# HDSC_HC32L166 register map
Vendor: HDSC Co.Ltd; Series: ARMCM0P; File version: 1.2
CPU: CM0 r0p0, little endian, no MPU, no FPU, 3 interrupt priority bits
Registers are 32-bit, read-write, reset 0x0 unless marked. A register's access mark holds for its fields unless they carry their own. Offsets are from the block's base; [hi:lo] are bit positions; {n}, {i} and the like mark numbered series; 'fields as' and 'values as' point back to an identical list.

## TIM0_MODE23
Base 0x40000C00; alternate view of TIM0_MODE0
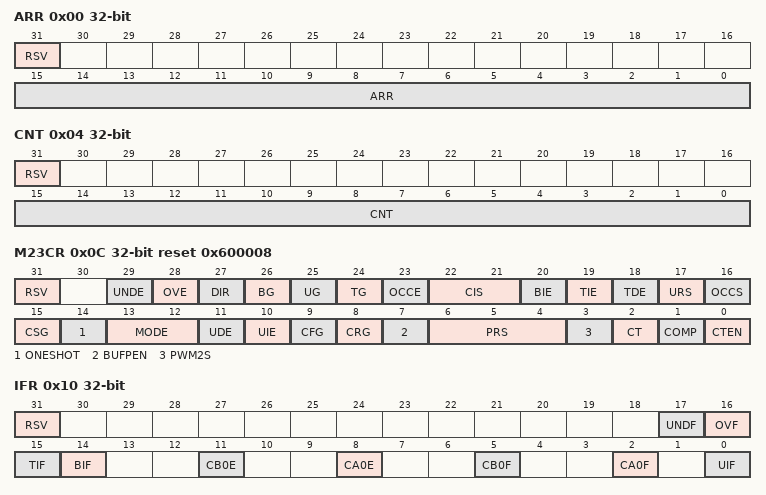
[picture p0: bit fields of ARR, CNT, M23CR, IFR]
0x00 ARR (reset mask 0xFFFF)
  [31] RSV, [15:0] ARR
0x04 CNT (reset mask 0xFFFF)
  [31] RSV, [15:0] CNT
0x0C M23CR reset 0x600008 (reset mask 0x3FFFFFFF)
  [31] RSV, [29] UNDE, [28] OVE, [27] DIR, [26] BG wo, [25] UG wo, [24] TG wo, [23] OCCE, [22:21] CIS, [20] BIE, [19] TIE, [18] TDE, [17] URS, [16] OCCS, [15] CSG, [14] ONESHOT, [13:12] MODE, [11] UDE, [10] UIE, [9] CFG, [8] CRG, [7] BUFPEN, [6:4] PRS, [3] PWM2S, [2] CT, [1] COMP, [0] CTEN
0x10 IFR ro (reset mask 0x3C925)
  [31] RSV, [17] UNDF, [16] OVF, [15] TIF, [14] BIF, [11] CB0E, [8] CA0E, [5] CB0F, [2] CA0F, [0] UIF
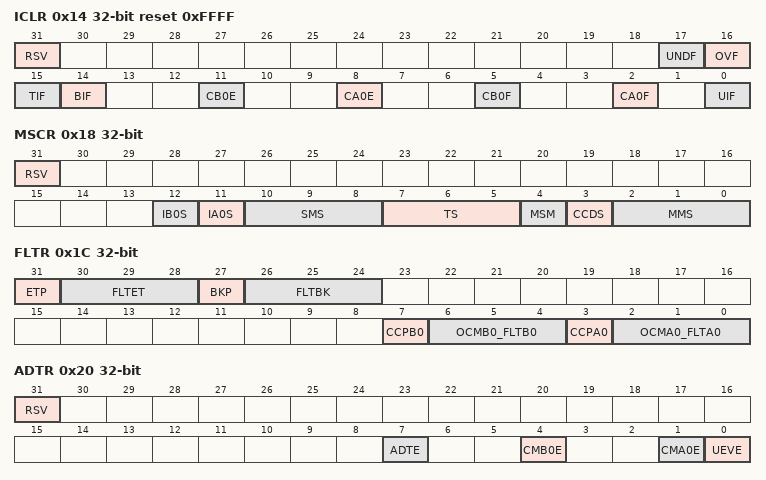
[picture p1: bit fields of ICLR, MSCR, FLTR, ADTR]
0x14 ICLR wo reset 0xFFFF (reset mask 0x3C925)
  [31] RSV rw, [17] UNDF rw, [16] OVF rw, [15] TIF, [14] BIF, [11] CB0E, [8] CA0E, [5] CB0F, [2] CA0F, [0] UIF
0x18 MSCR (reset mask 0x1FFF)
  [31] RSV, [12] IB0S, [11] IA0S, [10:8] SMS, [7:5] TS, [4] MSM, [3] CCDS, [2:0] MMS
0x1C FLTR
  [31] ETP, [30:28] FLTET, [27] BKP, [26:24] FLTBK, [7] CCPB0, [6:4] OCMB0_FLTB0, [3] CCPA0, [2:0] OCMA0_FLTA0
0x20 ADTR (reset mask 0x93)
  [31] RSV, [7] ADTE, [4] CMB0E, [1] CMA0E, [0] UEVE
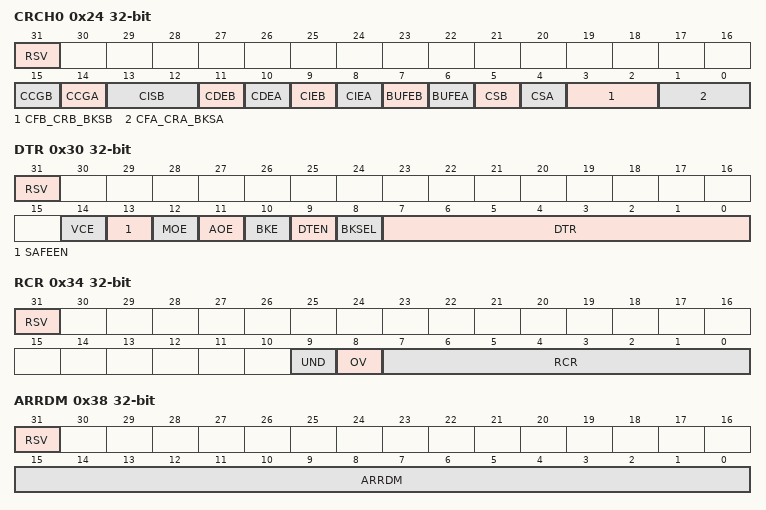
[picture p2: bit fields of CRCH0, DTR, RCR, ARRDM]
0x24 CRCH0 (reset mask 0xFFFF)
  [31] RSV, [15] CCGB, [14] CCGA, [13:12] CISB, [11] CDEB, [10] CDEA, [9] CIEB, [8] CIEA, [7] BUFEB, [6] BUFEA, [5] CSB, [4] CSA, [3:2] CFB_CRB_BKSB, [1:0] CFA_CRA_BKSA
0x30 DTR (reset mask 0x7FFF)
  [31] RSV, [14] VCE, [13] SAFEEN, [12] MOE, [11] AOE, [10] BKE, [9] DTEN, [8] BKSEL, [7:0] DTR
0x34 RCR (reset mask 0x3FF)
  [31] RSV, [9] UND, [8] OV, [7:0] RCR
0x38 ARRDM (reset mask 0xFFFF)
  [31] RSV, [15:0] ARRDM
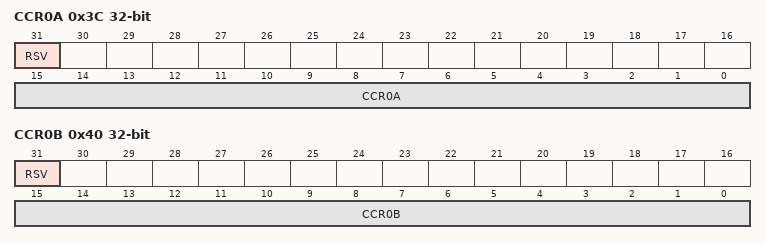
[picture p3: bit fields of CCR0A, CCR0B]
0x3C CCR0A (reset mask 0xFFFF)
  [31] RSV, [15:0] CCR0A
0x40 CCR0B (reset mask 0xFFFF)
  [31] RSV, [15:0] CCR0B

## TIM1_MODE23
Base 0x40000D00; alternate view of TIM1_MODE0
Registers as TIM0_MODE23.

## TIM2_MODE23
Base 0x40000E00; alternate view of TIM2_MODE0
Registers as TIM0_MODE23.

## TIM3_MODE23
Base 0x40005800; alternate view of TIM3_MODE0
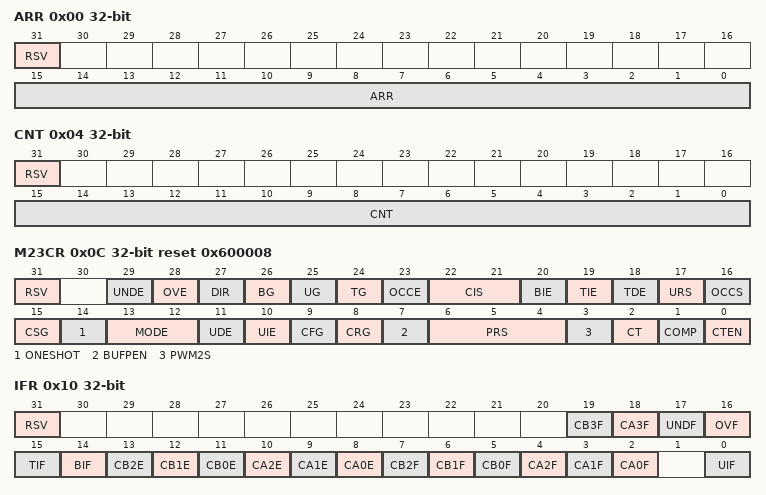
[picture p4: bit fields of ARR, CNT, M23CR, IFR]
0x00 ARR (reset mask 0xFFFF)
  [31] RSV, [15:0] ARR
0x04 CNT (reset mask 0xFFFF)
  [31] RSV, [15:0] CNT
0x0C M23CR reset 0x600008 (reset mask 0x3FFFFFFF)
  [31] RSV, [29] UNDE, [28] OVE, [27] DIR, [26] BG wo, [25] UG wo, [24] TG wo, [23] OCCE, [22:21] CIS, [20] BIE, [19] TIE, [18] TDE, [17] URS, [16] OCCS, [15] CSG, [14] ONESHOT, [13:12] MODE, [11] UDE, [10] UIE, [9] CFG, [8] CRG, [7] BUFPEN, [6:4] PRS, [3] PWM2S, [2] CT, [1] COMP, [0] CTEN
0x10 IFR ro (reset mask 0xFFFFD)
  [31] RSV, [19] CB3F, [18] CA3F, [17] UNDF, [16] OVF, [15] TIF, [14] BIF, [13] CB2E, [12] CB1E, [11] CB0E, [10] CA2E, [9] CA1E, [8] CA0E, [7] CB2F, [6] CB1F, [5] CB0F, [4] CA2F, [3] CA1F, [2] CA0F, [0] UIF
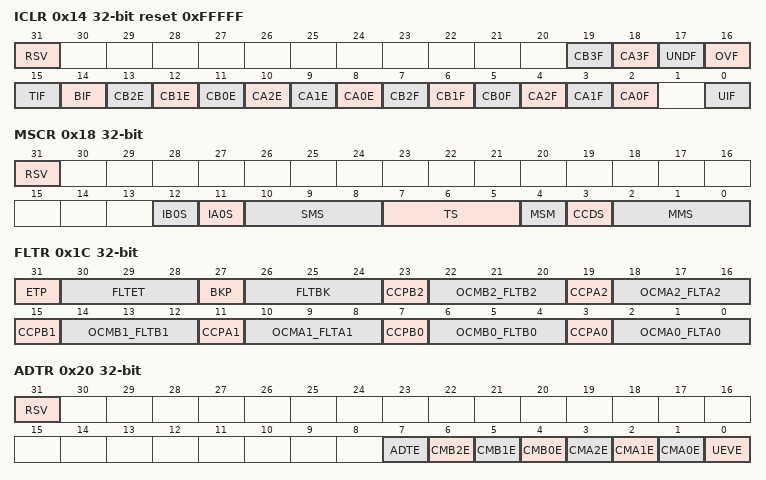
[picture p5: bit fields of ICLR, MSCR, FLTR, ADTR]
0x14 ICLR wo reset 0xFFFFF (reset mask 0xFFFFD)
  [31] RSV rw, [19] CB3F rw, [18] CA3F rw, [17] UNDF rw, [16] OVF rw, [15] TIF, [14] BIF, [13] CB2E, [12] CB1E, [11] CB0E, [10] CA2E, [9] CA1E, [8] CA0E, [7] CB2F, [6] CB1F, [5] CB0F, [4] CA2F, [3] CA1F, [2] CA0F, [0] UIF
0x18 MSCR (reset mask 0x1FFF)
  [31] RSV, [12] IB0S, [11] IA0S, [10:8] SMS, [7:5] TS, [4] MSM, [3] CCDS, [2:0] MMS
0x1C FLTR
  [31] ETP, [30:28] FLTET, [27] BKP, [26:24] FLTBK, [23] CCPB2, [22:20] OCMB2_FLTB2, [19] CCPA2, [18:16] OCMA2_FLTA2, [15] CCPB1, [14:12] OCMB1_FLTB1, [11] CCPA1, [10:8] OCMA1_FLTA1, [7] CCPB0, [6:4] OCMB0_FLTB0, [3] CCPA0, [2:0] OCMA0_FLTA0
0x20 ADTR (reset mask 0xFF)
  [31] RSV, [7] ADTE, [6] CMB2E, [5] CMB1E, [4] CMB0E, [3] CMA2E, [2] CMA1E, [1] CMA0E, [0] UEVE
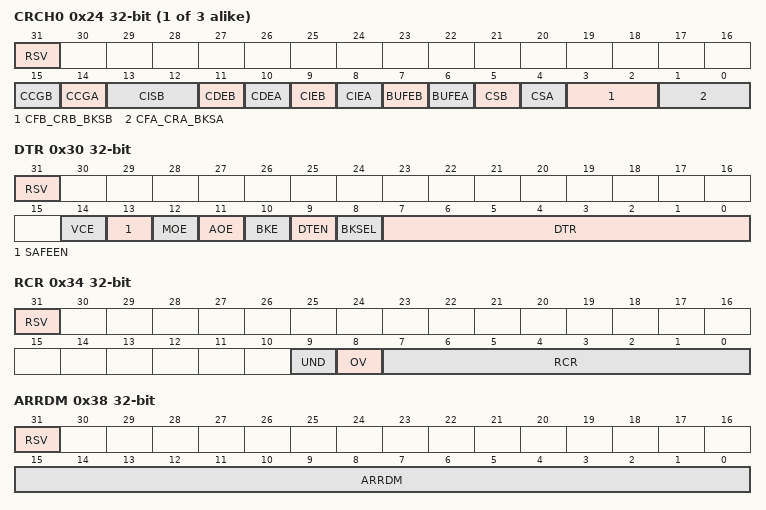
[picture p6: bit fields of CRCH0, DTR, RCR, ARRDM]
{0x24+4i} CRCH{i} (reset mask 0xFFFF) (i=0..2)
  [31] RSV, [15] CCGB, [14] CCGA, [13:12] CISB, [11] CDEB, [10] CDEA, [9] CIEB, [8] CIEA, [7] BUFEB, [6] BUFEA, [5] CSB, [4] CSA, [3:2] CFB_CRB_BKSB, [1:0] CFA_CRA_BKSA
0x30 DTR (reset mask 0x7FFF)
  [31] RSV, [14] VCE, [13] SAFEEN, [12] MOE, [11] AOE, [10] BKE, [9] DTEN, [8] BKSEL, [7:0] DTR
0x34 RCR (reset mask 0x3FF)
  [31] RSV, [9] UND, [8] OV, [7:0] RCR
0x38 ARRDM (reset mask 0xFFFF)
  [31] RSV, [15:0] ARRDM
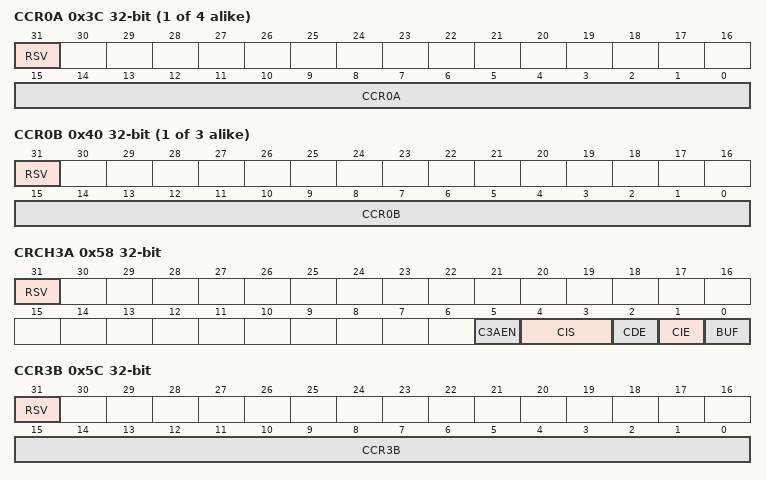
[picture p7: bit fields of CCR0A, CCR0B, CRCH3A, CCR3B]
{0x3C+8i} CCR{i}A (reset mask 0xFFFF) (i=0..3)
  [31] RSV, [15:0] CCR{i}A
{0x40+8i} CCR{i}B (reset mask 0xFFFF) (i=0..2)
  [31] RSV, [15:0] CCR{i}B
0x58 CRCH3A (reset mask 0x3F)
  [31] RSV, [5] C3AEN, [4:3] CIS, [2] CDE, [1] CIE, [0] BUF
0x5C CCR3B (reset mask 0xFFFF)
  [31] RSV, [15:0] CCR3B
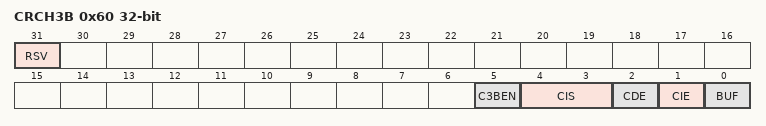
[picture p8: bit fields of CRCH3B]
0x60 CRCH3B (reset mask 0x3F)
  [31] RSV, [5] C3BEN, [4:3] CIS, [2] CDE, [1] CIE, [0] BUF

## TRNG
Base 0x40004C00
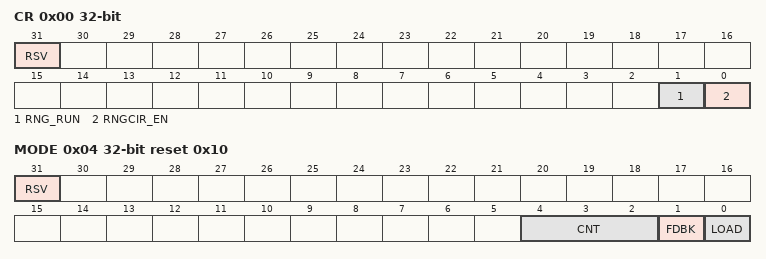
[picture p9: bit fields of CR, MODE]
0x00 CR (reset mask 0x3)
  [31] RSV, [1] RNG_RUN, [0] RNGCIR_EN
0x04 MODE reset 0x10 (reset mask 0x1F)
  [31] RSV, [4:2] CNT, [1] FDBK, [0] LOAD
0x0C DATA0 ro
0x10 DATA1 ro

## UART0 — desc UART
Base 0x40000000
Same registers: UART1 0x40000100, UART2 0x40006000, UART3 0x40006400
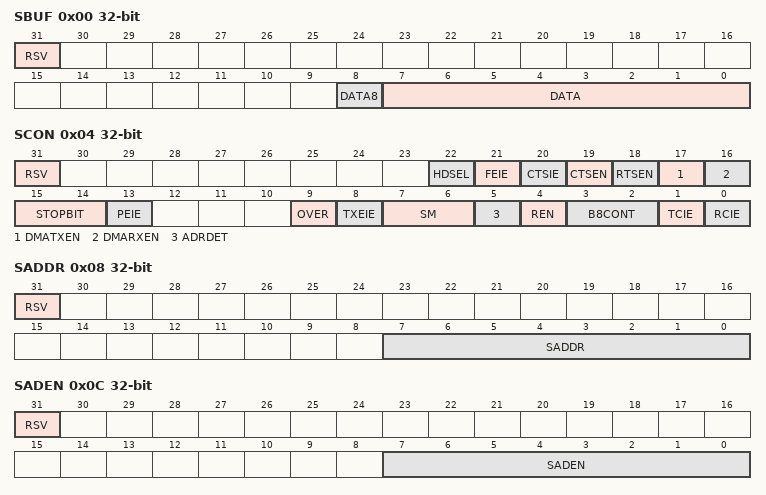
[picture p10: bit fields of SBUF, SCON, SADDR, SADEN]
0x00 SBUF (reset mask 0x1FF)
  [31] RSV, [8] DATA8, [7:0] DATA
0x04 SCON (reset mask 0x7FE3FF)
  [31] RSV, [22] HDSEL, [21] FEIE, [20] CTSIE, [19] CTSEN, [18] RTSEN, [17] DMATXEN, [16] DMARXEN, [15:14] STOPBIT, [13] PEIE, [9] OVER, [8] TXEIE, [7:6] SM, [5] ADRDET, [4] REN, [3:2] B8CONT, [1] TCIE, [0] RCIE
0x08 SADDR (reset mask 0xFF)
  [31] RSV, [7:0] SADDR
0x0C SADEN (reset mask 0xFF)
  [31] RSV, [7:0] SADEN
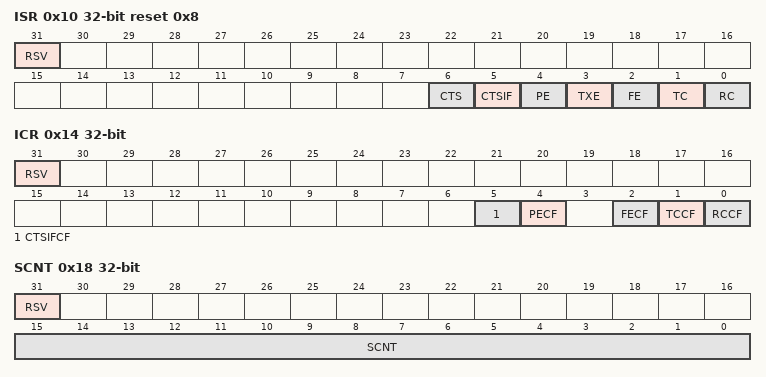
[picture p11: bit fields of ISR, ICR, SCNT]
0x10 ISR ro reset 0x8 (reset mask 0x7F)
  [31] RSV rw, [6] CTS, [5] CTSIF, [4] PE, [3] TXE, [2] FE, [1] TC, [0] RC
0x14 ICR wo (reset mask 0x37)
  [31] RSV rw, [5] CTSIFCF, [4] PECF, [2] FECF, [1] TCCF, [0] RCCF
0x18 SCNT (reset mask 0xFFFF)
  [31] RSV, [15:0] SCNT

## VC
Base 0x40002400; alternate view of ADC
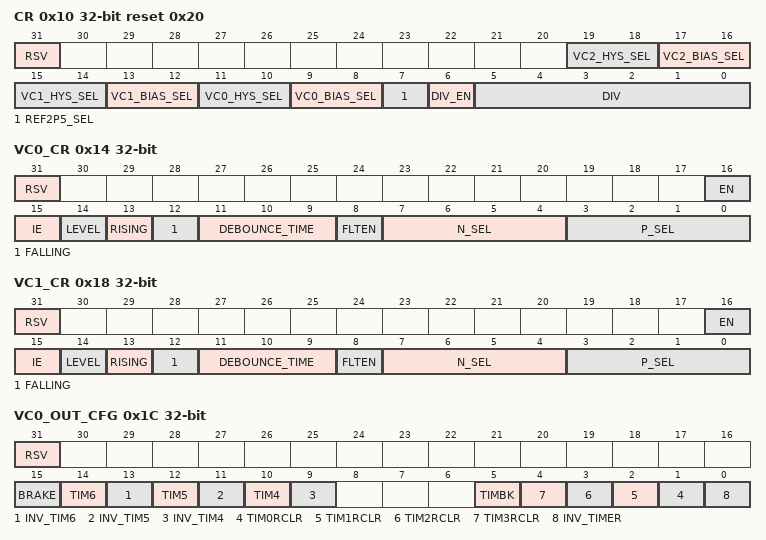
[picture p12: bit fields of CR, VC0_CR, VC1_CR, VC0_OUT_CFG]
0x10 CR reset 0x20 (reset mask 0xFFFFF)
  [31] RSV, [19:18] VC2_HYS_SEL, [17:16] VC2_BIAS_SEL, [15:14] VC1_HYS_SEL, [13:12] VC1_BIAS_SEL, [11:10] VC0_HYS_SEL, [9:8] VC0_BIAS_SEL, [7] REF2P5_SEL, [6] DIV_EN, [5:0] DIV
0x14 VC0_CR (reset mask 0x1FFFF)
  [31] RSV, [16] EN, [15] IE, [14] LEVEL, [13] RISING, [12] FALLING, [11:9] DEBOUNCE_TIME, [8] FLTEN, [7:4] N_SEL, [3:0] P_SEL
0x18 VC1_CR (reset mask 0x1FFFF)
  fields as VC0_CR
0x1C VC0_OUT_CFG (reset mask 0xFE3F)
  [31] RSV, [15] BRAKE, [14] TIM6, [13] INV_TIM6, [12] TIM5, [11] INV_TIM5, [10] TIM4, [9] INV_TIM4, [5] TIMBK, [n+1] TIM{n}RCLR (n=0..3), [0] INV_TIMER
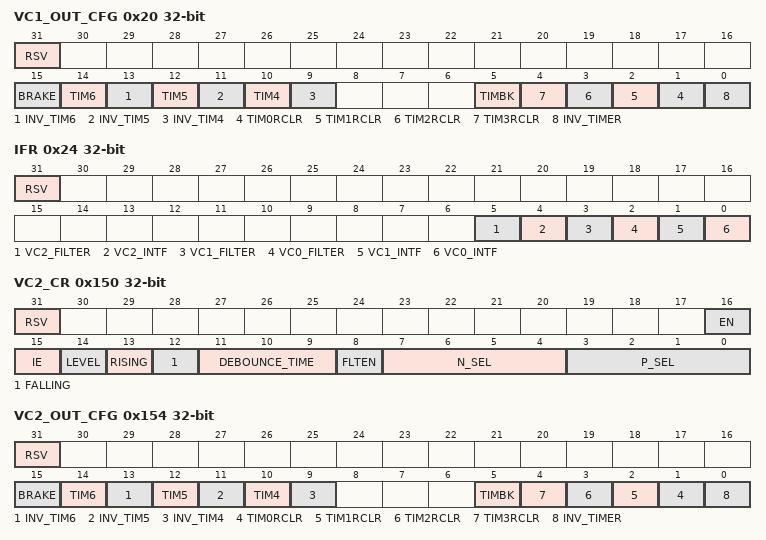
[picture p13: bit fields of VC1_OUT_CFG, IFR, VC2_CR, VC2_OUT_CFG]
0x20 VC1_OUT_CFG (reset mask 0xFEFF)
  fields as VC0_OUT_CFG
0x24 IFR (reset mask 0x3F)
  [31] RSV, [5] VC2_FILTER ro, [4] VC2_INTF, [3] VC1_FILTER ro, [2] VC0_FILTER ro, [1] VC1_INTF, [0] VC0_INTF
0x150 VC2_CR (reset mask 0x1FFFF)
  fields as VC0_CR
0x154 VC2_OUT_CFG (reset mask 0xFEFF)
  fields as VC0_OUT_CFG

## WDT
Base 0x40000F80
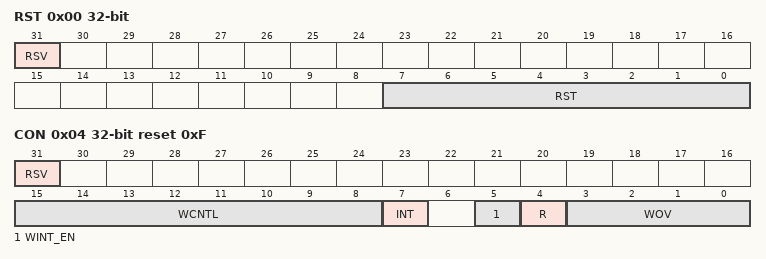
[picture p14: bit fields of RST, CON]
0x00 RST wo (reset mask 0xFF)
  [31] RSV rw, [7:0] RST
0x04 CON reset 0xF (reset mask 0xFFBF)
  [31] RSV, [15:8] WCNTL ro, [7] INT ro, [5] WINT_EN, [4] R ro, [3:0] WOV

## WWDT
Base 0x40007800
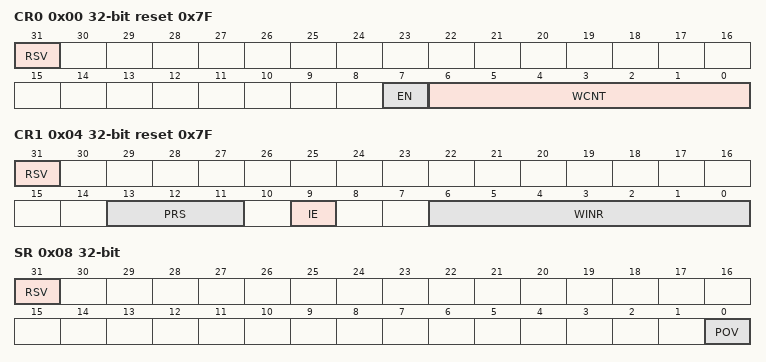
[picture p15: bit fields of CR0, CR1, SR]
0x00 CR0 reset 0x7F (reset mask 0xFF)
  [31] RSV, [7] EN, [6:0] WCNT
0x04 CR1 reset 0x7F (reset mask 0x3A7F)
  [31] RSV, [13:11] PRS, [9] IE, [6:0] WINR
0x08 SR (reset mask 0x1)
  [31] RSV, [0] POV
